VERSION "DBC_GENERAL_RELAIS"

NS_ :

BS_:

BU_:

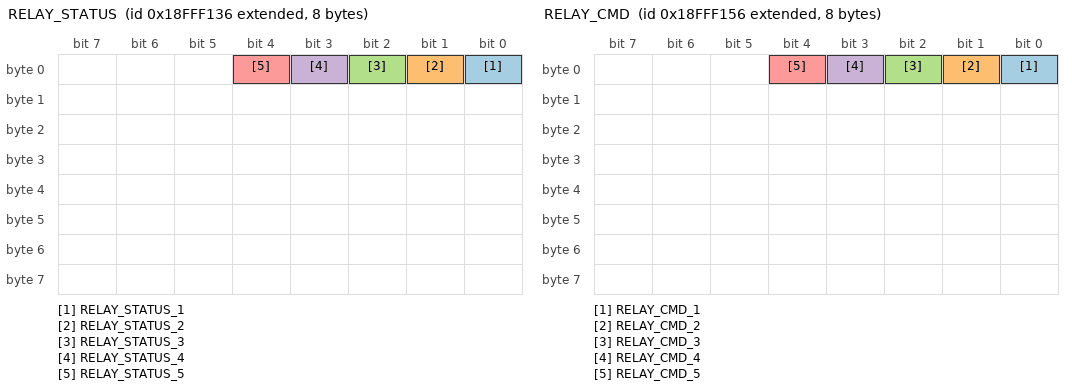
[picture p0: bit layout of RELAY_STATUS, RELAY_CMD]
BO_ 2566910262 RELAY_STATUS: 8 Vector__XXX
 SG_ RELAY_STATUS_1 : 0|1@1+ (1,0) [0|1] "Binary" Vector__XXX
 SG_ RELAY_STATUS_2 : 1|1@1+ (1,0) [0|1] "Binary" Vector__XXX
 SG_ RELAY_STATUS_3 : 2|1@1+ (1,0) [0|1] "Binary" Vector__XXX
 SG_ RELAY_STATUS_4 : 3|1@1+ (1,0) [0|1] "Binary" Vector__XXX
 SG_ RELAY_STATUS_5 : 4|1@1+ (1,0) [0|1] "Binary" Vector__XXX

BO_ 2566910263 ANALOG_STATUS_1_2: 8 Vector__XXX
 SG_ ANALOG_IN_STATUS_1 : 0|32@1+ (0.0002,0) [0|11.34] "V" Vector__XXX
 SG_ ANALOG_IN_STATUS_2 : 32|32@1+ (0.0002,0) [0|11.34] "V" Vector__XXX

BO_ 2566910264 ANALOG_STATUS_3_4: 8 Vector__XXX
 SG_ ANALOG_IN_STATUS_4 : 32|32@1+ (0.0002,0) [0|11.34] "V" Vector__XXX
 SG_ ANALOG_IN_STATUS_3 : 0|32@1+ (0.0002,0) [0|11.34] "V" Vector__XXX

BO_ 2566910265 ANALOG_STATUS_5_6: 8 Vector__XXX
 SG_ ANALOG_IN_STATUS_6 : 32|32@1+ (0.0002,0) [0|11.34] "V" Vector__XXX
 SG_ ANALOG_IN_STATUS_5 : 0|32@1+ (0.0002,0) [0|11.34] "V" Vector__XXX

BO_ 2566910272 ANALOG_STATUS_7: 8 Vector__XXX
 SG_ ANALOG_IN_STATUS_7 : 0|32@1+ (0.0002,0) [0|11.34] "V" Vector__XXX

BO_ 2566910294 RELAY_CMD: 8 Vector__XXX
 SG_ RELAY_CMD_1 : 0|1@1+ (1,0) [0|1] "Binary" Vector__XXX
 SG_ RELAY_CMD_2 : 1|1@1+ (1,0) [0|1] "Binary" Vector__XXX
 SG_ RELAY_CMD_3 : 2|1@1+ (1,0) [0|1] "Binary" Vector__XXX
 SG_ RELAY_CMD_4 : 3|1@1+ (1,0) [0|1] "Binary" Vector__XXX
 SG_ RELAY_CMD_5 : 4|1@1+ (1,0) [0|1] "Binary" Vector__XXX

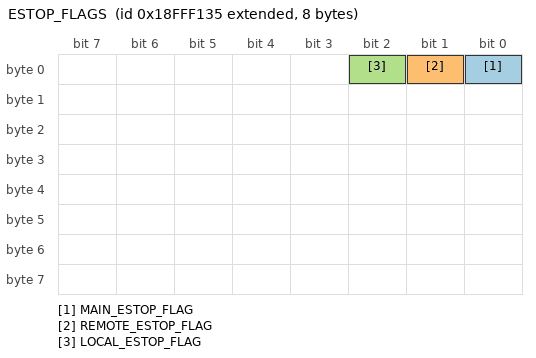
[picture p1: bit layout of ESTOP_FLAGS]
BO_ 2566910261 ESTOP_FLAGS: 8 Vector__XXX
 SG_ MAIN_ESTOP_FLAG : 0|1@1+ (1,0) [0|1] "Binary" Vector__XXX
 SG_ REMOTE_ESTOP_FLAG : 1|1@1+ (1,0) [0|1] "Binary" Vector__XXX
 SG_ LOCAL_ESTOP_FLAG : 2|1@1+ (1,0) [0|1] "Binary" Vector__XXX

BA_DEF_ BO_  "VFrameFormat" ENUM  "StandardCAN","ExtendedCAN","reserved","J1939PG";
BA_DEF_  "DatabaseVersion" STRING ;
BA_DEF_  "BusType" STRING ;
BA_DEF_  "ProtocolType" STRING ;
BA_DEF_  "DatabaseCompiler" STRING ;
BA_DEF_DEF_  "VFrameFormat" "J1939PG";
BA_DEF_DEF_  "DatabaseVersion" "DEMO PLUS";
BA_DEF_DEF_  "BusType" "";
BA_DEF_DEF_  "ProtocolType" "";
BA_DEF_DEF_  "DatabaseCompiler" "";
BA_ "DatabaseVersion" "1.0.0";
BA_ "DatabaseCompiler" "CSS ELECTRONICS (WWW.CSSELECTRONICS.COM)";
BA_ "BusType" "CAN";
BA_ "ProtocolType" "J1939";
BA_ "VFrameFormat" BO_ 2566910262 1;
BA_ "VFrameFormat" BO_ 2566910272 1;
BA_ "VFrameFormat" BO_ 2566910265 1;
BA_ "VFrameFormat" BO_ 2566910263 1;
BA_ "VFrameFormat" BO_ 2566910264 1;
BA_ "VFrameFormat" BO_ 2566910294 1;
